# SAM9X75D1G device description
Architecture: ARM926EJ-S; Family: SAM9; Series: SAM9X7
Registers are 32-bit, read-write, reset 0x0 unless marked. A register's access mark holds for its fields unless they carry their own. Offsets are from the block's base; [hi:lo] are bit positions; lines under a group give offsets from that group; {n}, {i} and the like mark numbered series; 'fields as' and 'values as' point back to an identical list.

## LCDC (part 2 of 2) — LCD Controller
Instances: XLCDC 0xF8038000
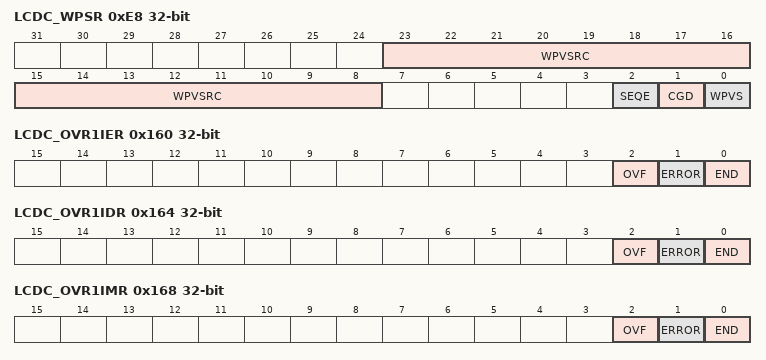
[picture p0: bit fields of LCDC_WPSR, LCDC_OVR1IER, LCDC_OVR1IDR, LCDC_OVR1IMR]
0xE8 LCDC_WPSR ro — Write Protection Status Register
  [23:8] WPVSRC — Write Protection Violation Source
  [2] SEQE — Internal Sequencer Error (cleared on read)
    0=No peripheral internal sequencer error has occurred since the last read of LCDC_WPSR; 1=A peripheral internal sequencer error has occurred since the last read of LCDC_WPSR. This flag can only be set under abnormal operating conditions.
  [1] CGD — Clock Glitch Detected (cleared on read)
    0=The clock monitoring circuitry has not been corrupted since the last read of LCDC_WPSR. Under normal operating conditions, this bit is always cleared.; 1=The clock monitoring circuitry has been corrupted since the last read of LCDC_WPSR. This flag can only be set in case of an abnormal clock signal waveform (glitch).
  [0] WPVS — Write Protection Violation Status
0x160 LCDC_OVR1IER wo reset not defined (atomic set of LCDC_OVR1IMR) — Overlay 1 Interrupt Enable Register
  [2] OVF — Overflow Interrupt Enable
  [1] ERROR — Transfer Error Detected Interrupt Enable
  [0] END — End of Frame DMA Transfer Interrupt Enable
0x164 LCDC_OVR1IDR wo reset not defined (atomic clear of LCDC_OVR1IMR) — Overlay 1 Interrupt Disable Register
  [2] OVF — Overflow Interrupt Disable
  [1] ERROR — Error Interrupt Disable
  [0] END — End of Frame DMA Transfer Interrupt Disable
0x168 LCDC_OVR1IMR ro — Overlay 1 Interrupt Mask Register
  [2] OVF — Overflow Interrupt Mask
  [1] ERROR — Bus Error Detected Interrupt Mask
  [0] END — End of Frame DMA Transfer Interrupt Mask
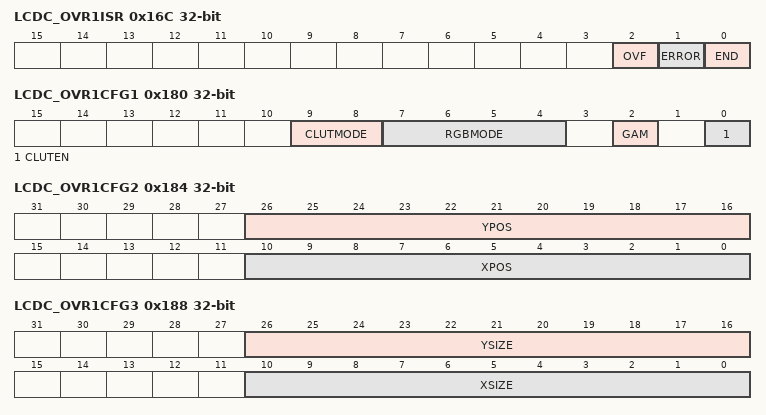
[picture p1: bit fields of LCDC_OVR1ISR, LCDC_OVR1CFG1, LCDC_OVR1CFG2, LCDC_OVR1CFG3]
0x16C LCDC_OVR1ISR ro — Overlay 1 Interrupt Status Register
  [2] OVF — Overflow Detected
    0=No overflow occurred since last read of LCDC_OVR1ISR; 1=An overflow occurred, at least one DMA transfer is still running at the End Of Frame. This flag is reset after a read operation
  [1] ERROR — Bus Error Detected
    0=No system bus error has been detected since the last read of LCDC_OVR1ISR; 1=A system bus error has been detected. This flag is reset after a read operation
  [0] END — End of Frame DMA Transfer
    0=No end of transfer has been detected since last read of LCDC_OVR1ISR; 1=End of transfer has been detected. This flag is reset after a read operation.
0x170 LCDC_OVR1EN — Overlay 1 Enable Register
  [0] ENABLE — Layer Enable
    0=The layer is disabled; 1=The layer is enabled
0x174 LCDC_OVR1CLA — Overlay 1 Color Table Address Register
  [31:2] CLA — Overlay 1 CLUT Address
0x178 LCDC_OVR1FBA — Overlay 1 Frame Buffer Address Register
  [31:0] FBA — Frame Buffer Address
0x17C LCDC_OVR1CFG0 — Overlay 1 Configuration Register 0
  [6:4] BLEN — System Bus Burst Length
    0=INCR1 (System bus access is started as soon as there is enough space in the FIFO to store one data.); 1=INCR4 (System bus access is started as soon as there is enough space in the FIFO to store a total amount of 4 data. A system bus INCR4 Burst is used by default. INCR1 is used for bursts less than 4.); 2=INCR8 (System bus access is started as soon as there is enough space in the FIFO to store a total amount of 8 data. A system bus INCR8 Burst is used by default. INCR4 bursts are used for burst of 4 beats. INCR1 is used for bursts less than 4.); 3=INCR16 (System bus access is started as soon as there is enough space in the FIFO to store a total amount of 16 data. A system bus INCR16 Burst is used by default. INCR8 and INCR4 bursts are respectively used for burst of 8 and 4 beats. INCR1 is used for bursts less than 4.); 4=INCR32 (System bus access is started as soon as there is enough space in the FIFO to store a total amount of 32 data. A system bus INCR32 Burst is used by default. INCR16, INCR8 and INCR4 bursts are respectively used for burst of 16, 8 and 4 beats. INCR1 is used for bursts less than 4.)
0x180 LCDC_OVR1CFG1 — Overlay 1 Configuration Register 1
  [9:8] CLUTMODE — CLUT Mode Input Selection
    0=CLUT_1BPP (CLUT mode set to 1 bit per pixel); 1=CLUT_2BPP (CLUT mode set to 2 bits per pixel); 2=CLUT_4BPP (CLUT mode set to 4 bits per pixel); 3=CLUT_8BPP (CLUT mode set to 8 bits per pixel)
  [7:4] RGBMODE — RGB Mode Input Selection
    0=12BPP_RGB_444; 1=16BPP_ARGB_4444; 2=16BPP_RGBA_4444; 3=16BPP_RGB_565; 4=16BPP_ARGB_1555; 5=18BPP_RGB_666; 6=18BPP_RGB_666PACKED; 7=19BPP_ARGB_1666; 8=19BPP_ARGB_PACKED (19 bpp ARGB 1666 PACKED); 9=24BPP_RGB_888; 10=24BPP_RGB_888_PACKED; 11=25BPP_ARGB_1888; 12=32BPP_ARGB_8888; 13=32BPP_RGBA_8888
  [2] GAM — Gamma Correction
    0=Gamma correction is disabled; 1=Gamma correction is enabled
  [0] CLUTEN — CLUT Mode Enable
    0=RGB mode is selected; 1=CLUT mode is selected
0x184 LCDC_OVR1CFG2 — Overlay 1 Configuration Register 2
  [26:16] YPOS — Vertical Window Position
  [10:0] XPOS — Horizontal Window Position
0x188 LCDC_OVR1CFG3 — Overlay 1 Configuration Register 3
  [26:16] YSIZE — Vertical Window Size
  [10:0] XSIZE — Horizontal Window Size
0x18C LCDC_OVR1CFG4 — Overlay 1 Configuration Register 4
  [31:0] XSTRIDE — Horizontal Stride
0x190 LCDC_OVR1CFG5 — Overlay 1 Configuration Register 5
  [31:0] PSTRIDE — Pixel Stride
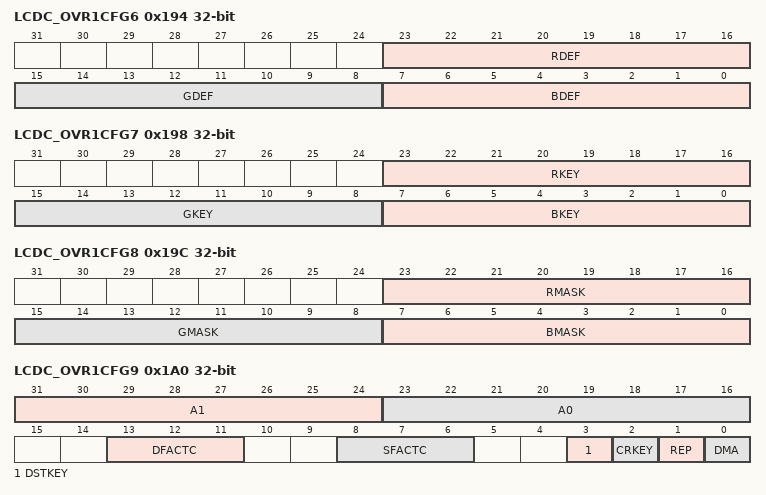
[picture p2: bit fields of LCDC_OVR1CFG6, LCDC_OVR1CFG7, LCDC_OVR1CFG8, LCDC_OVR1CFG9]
0x194 LCDC_OVR1CFG6 — Overlay 1 Configuration Register 6
  [23:16] RDEF — Red Default
  [15:8] GDEF — Green Default
  [7:0] BDEF — Blue Default
0x198 LCDC_OVR1CFG7 — Overlay 1 Configuration Register 7
  [23:16] RKEY — Red Color Component Chroma Key
  [15:8] GKEY — Green Color Component Chroma Key
  [7:0] BKEY — Blue Color Component Chroma Key
0x19C LCDC_OVR1CFG8 — Overlay 1 Configuration Register 8
  [23:16] RMASK — Red Color Component Chroma Key Mask
  [15:8] GMASK — Green Color Component Chroma Key Mask
  [7:0] BMASK — Blue Color Component Chroma Key Mask
0x1A0 LCDC_OVR1CFG9 — Overlay 1 Configuration Register 9
  [31:24] A1 — Alpha 1 Value
  [23:16] A0 — Alpha 0 Value
  [13:11] DFACTC — Destination Factor for the Blending Equation of the Color Component
    0=ZERO (Sets the factor to 0.0.); 1=ONE (Sets the factor to 1.0.); 2=A0 (Sets the factor to A0/255.); 3=A1 (Sets the factor to A1/255.); 4=A0_MULT_AD (Sets the factor to A0 multiplied by Destination Alpha.); 5=M_A0_MULT_AD (Sets the factor to A0 multiplied by Destination Alpha, then sets the factor to one minus the result.); 6=M_A0_MUL_AS (Computes A0 multiplied by source alpha0, then sets the factor to one minus the result.); 7=M_A0 (Computes one minus A0, then sets the factor to one minus the result.)
  [8:6] SFACTC — Source Factor for the Blending Equation of the Color Component
    0=ONE (Sets the factor to 1.0.); 1=ZERO (Sets the factor to 0.0.); 2=A0 (Sets the factor to A0/255.); 3=A0_MULT_AD (Sets the factor to A0 multiplied by Destination Alpha.); 4=A0_MUL_AS (Sets the factor to A0 multiplied by Source Alpha.); 5=M_A0_MUL_AD (Computes A0 multiplied by Destination Alpha, then sets the factor to minus the result .)
  [3] DSTKEY — Destination Color Keying
    0=When CRKEY is enabled, color key is applied on OVR1 pixels, before the blending operation; 1=When CRKEY is enabled, color key is applied on OVR1 pixels, after the blending operation
  [2] CRKEY — Chroma Keying Enable
  [1] REP — Replication Logic
    0=When the selected pixel depth is less than 24 bpp, the pixel is shifted and LSBs are set to 0; 1=When the selected pixel depth is less than 24 bpp, the pixel is shifted and the LSB replicates the MSB
  [0] DMA — DMA Enable
    0=The pixel for the current layer is retrieved from the default color register; 1=The pixel stream is retrieved from the memory
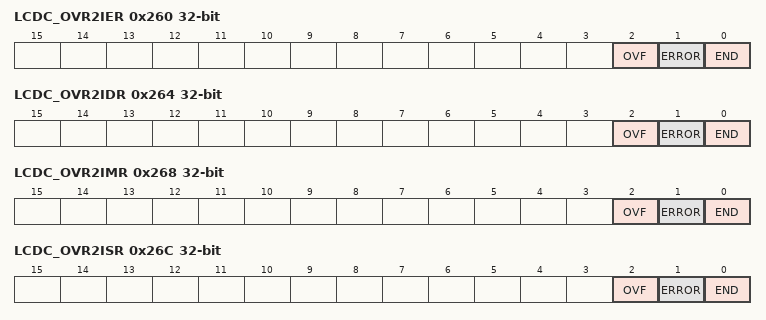
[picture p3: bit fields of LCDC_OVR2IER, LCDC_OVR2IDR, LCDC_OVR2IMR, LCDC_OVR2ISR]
0x260 LCDC_OVR2IER wo reset not defined (atomic set of LCDC_OVR2IMR) — Overlay 2 Interrupt Enable Register
  [2] OVF — Overflow Interrupt Enable
  [1] ERROR — Bus Transfer Error Detected Interrupt Enable
  [0] END — End of Frame DMA Transfer Interrupt Enable
0x264 LCDC_OVR2IDR wo reset not defined (atomic clear of LCDC_OVR2IMR) — Overlay 2 Interrupt Disable Register
  [2] OVF — Overflow Interrupt Disable
  [1] ERROR — Bus Transfer Error Detected Interrupt Disable
  [0] END — End of Frame DMA Transfer Interrupt Disable
0x268 LCDC_OVR2IMR ro — Overlay 2 Interrupt Mask Register
  [2] OVF — Overflow Interrupt Mask
  [1] ERROR — Bus Transfer Error Detected Interrupt Mask
  [0] END — End of Frame DMA Transfer Interrupt Mask
0x26C LCDC_OVR2ISR ro — Overlay 2 Interrupt Status Register
  [2] OVF — Overflow Detected
    0=No overflow occurred since last read of LCDC_OVR2ISR; 1=An overflow occurred, at least one DMA transfer is still running at the End Of Frame. This flag is reset after a read operation
  [1] ERROR — Bus Error Detected
    0=No system bus error has been detected since the last read of LCDC_OVR2ISR; 1=A system bus error has been detected. This flag is reset after a read operation
  [0] END — End of Frame DMA Transfer
    0=No end of transfer has been detected since last read of LCDC_OVR2ISR; 1=End of transfer has been detected. This flag is reset after a read operation.
0x270 LCDC_OVR2EN — Overlay 2 Enable Register
  fields as LCDC_OVR1EN
0x274 LCDC_OVR2CLA — Overlay 2 Color Table Address Register
  [31:2] CLA — Overlay 2 CLUT Address
0x278 LCDC_OVR2FBA — Overlay 2 Frame Buffer Address Register
  [31:0] FBA — Frame Buffer Address
0x27C LCDC_OVR2CFG0 — Overlay 2 Configuration Register 0
  [6:4] BLEN — System Bus Burst Length
    0=INCR1 (System bus access is started as soon as there is enough space in the FIFO to store one data.); 1=INCR4 (System bus access is started as soon as there is enough space in the FIFO to store a total amount of 4 data. A system bus INCR4 Burst is used by default. INCR1 is used for bursts less than 4.); 2=INCR8 (System bus access is started as soon as there is enough space in the FIFO to store a total amount of 8 data. A system bus INCR8 Burst is used by default. INCR4 bursts are used for bursts of 4 beats. INCR1 is used for bursts less than 4.); 3=INCR16 (System bus access is started as soon as there is enough space in the FIFO to store a total amount of 16 data. A system bus INCR16 Burst is used by default. INCR8 and INCR4 bursts are respectively used for bursts of 8 and 4 beats. INCR1 is used for bursts less than 4.); 4=INCR32 (System bus access is started as soon as there is enough space in the FIFO to store a total amount of 32 data. A system bus INCR32 Burst is used by default. INCR16, INCR8 and INCR4 bursts are respectively used for bursts of 16, 8 and 4 beats. INCR1 is used for bursts less than 4.)
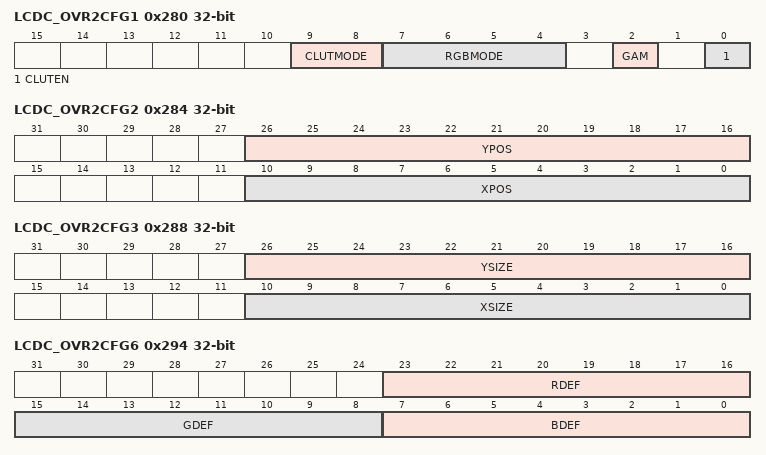
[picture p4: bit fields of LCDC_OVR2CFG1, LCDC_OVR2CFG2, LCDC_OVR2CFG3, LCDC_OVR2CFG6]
0x280 LCDC_OVR2CFG1 — Overlay 2 Configuration Register 1
  fields as LCDC_OVR1CFG1
0x284 LCDC_OVR2CFG2 — Overlay 2 Configuration Register 2
  fields as LCDC_OVR1CFG2
0x288 LCDC_OVR2CFG3 — Overlay 2 Configuration Register 3
  fields as LCDC_OVR1CFG3
0x28C LCDC_OVR2CFG4 — Overlay 2 Configuration Register 4
  [31:0] XSTRIDE — Horizontal Stride
0x290 LCDC_OVR2CFG5 — Overlay 2 Configuration Register 5
  [31:0] PSTRIDE — Pixel Stride
0x294 LCDC_OVR2CFG6 — Overlay 2 Configuration Register 6
  fields as LCDC_OVR1CFG6
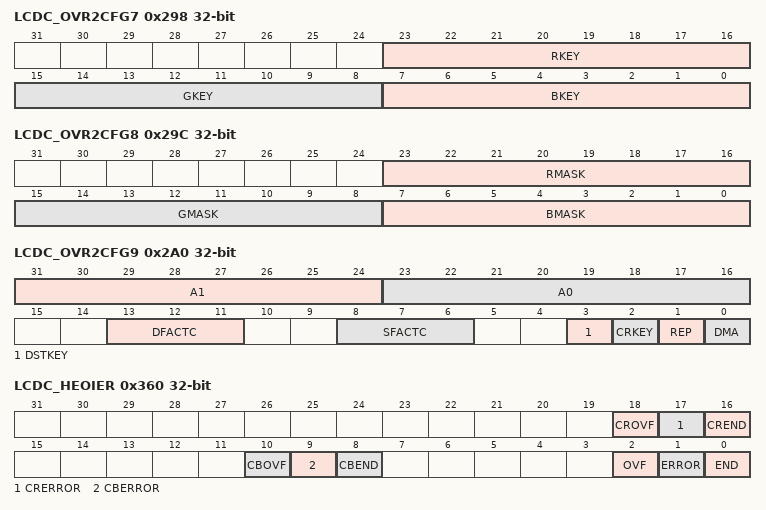
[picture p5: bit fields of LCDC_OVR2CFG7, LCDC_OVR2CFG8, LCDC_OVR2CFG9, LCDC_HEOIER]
0x298 LCDC_OVR2CFG7 — Overlay 2 Configuration Register 7
  fields as LCDC_OVR1CFG7
0x29C LCDC_OVR2CFG8 — Overlay 2 Configuration Register 8
  fields as LCDC_OVR1CFG8
0x2A0 LCDC_OVR2CFG9 — Overlay 2 Configuration Register 9
  [31:24] A1 — Alpha 1 Value
  [23:16] A0 — Alpha 0 Value
  [13:11] DFACTC — Destination Factor for the Blending Equation of the Color Component
    0=ZERO (Sets the factor to 0.0.); 1=ONE (Sets the factor to 1.0.); 2=A0 (Sets the factor to A0/255.); 3=A1 (Sets the factor to A1/255.); 4=A0_MULT_AD (Sets the factor to A0 multiplied by Destination Alpha.); 5=M_A0_MULT_AD (Sets the factor to A0 multiplied by Destination Alpha, then set the factor one minus the result.); 6=M_A0_MUL_AS (Computes A0 multiplied by source alpha0, then sets the factor to one minus the result.); 7=M_A0 (Computes one minus A0, then sets the factor to one minus the result.)
  [8:6] SFACTC — Source Factor for the Blending Equation of the Color Component
    0=ONE (Sets the factor to 1.0.); 1=ZERO (Sets the factor to 0.0.); 2=A0 (Sets the factor to A0/255.); 3=A0_MULT_AD (Sets the factor to A0 multiplied by Destination Alpha.); 4=A0_MUL_AS (Sets the factor to A0 multiplied by Source Alpha.); 5=M_A0_MUL_AD (Computes A0 multiplied by Destination Alpha, then sets the factor to minus the result.)
  [3] DSTKEY — Destination Color Keying
    0=When CRKEY is enabled, color key is applied on OVR2 pixels, before the blending operation; 1=When CRKEY is enabled, color key is applied on OVR2 pixels, after the blending operation
  [2] CRKEY — Chroma Keying
  [1] REP — Replication Logic
    values as LCDC_OVR1CFG9.REP
  [0] DMA — DMA Enable
    values as LCDC_OVR1CFG9.DMA
0x360 LCDC_HEOIER wo reset not defined (atomic set of LCDC_HEOIMR) — High-End Overlay Interrupt Enable Register
  [18] CROVF — Overflow for Cr Chroma Plane Interrupt Enable
  [17] CRERROR — Bus Transfer Error Detected for Cr Chroma Plane Interrupt Enable
  [16] CREND — End of Frame DMA for Cr Chroma Plane Transfer Interrupt Enable
  [10] CBOVF — Overflow for Cb or CbCr Chroma Plane Interrupt Enable
  [9] CBERROR — Bus Transfer Error Detected for Cb or CbCr Chroma Plane Interrupt Enable
  [8] CBEND — End of Frame DMA Transfer for Cb or CbCr Chroma Plane Interrupt Enable
  [2] OVF — Overflow Interrupt Enable
  [1] ERROR — Bus Transfer Error Detected Interrupt Enable
  [0] END — End of Frame DMA Transfer Interrupt Enable
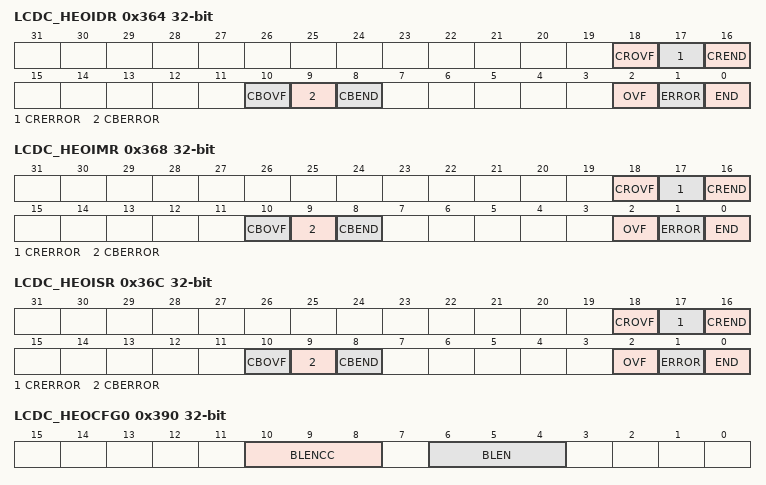
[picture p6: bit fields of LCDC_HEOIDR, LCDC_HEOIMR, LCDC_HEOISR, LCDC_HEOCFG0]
0x364 LCDC_HEOIDR wo reset not defined (atomic clear of LCDC_HEOIMR) — High-End Overlay Interrupt Disable Register
  [18] CROVF — Overflow for Cr Chroma Plane Interrupt Disable
  [17] CRERROR — Bus Transfer Error Detected for Cr Chroma Plane Interrupt Disable
  [16] CREND — End of Frame DMA Transfer for Cr Chroma Plane Interrupt Disable
  [10] CBOVF — Overflow for Cb or CbCr Chroma Plane Interrupt Disable
  [9] CBERROR — Bus Transfer Error Detected for Cb or CbCr Chroma Plane Interrupt Disable
  [8] CBEND — End of Frame DMA Transfer for Cb or CbCr Chroma Plane Interrupt Disable
  [2] OVF — Overflow Interrupt Disable
  [1] ERROR — Bus Transfer Error Detected Interrupt Disable
  [0] END — End of Frame DMA Transfer Interrupt Disable
0x368 LCDC_HEOIMR ro — High-End Overlay Interrupt Mask Register
  [18] CROVF — Overflow for Cr Chroma Plane Interrupt Mask
  [17] CRERROR — Bus Transfer Error Detected for Cr Chroma Plane Interrupt Mask
  [16] CREND — End of Frame DMA Transfer for Cr Chroma Plane Interrupt Mask
  [10] CBOVF — Overflow for Cb or CbCr Chroma Plane Interrupt Mask
  [9] CBERROR — Bus Transfer Error Detected for Cb or CbCr Chroma Plane Interrupt Mask
  [8] CBEND — End of Frame DMA Transfer for Cb or CbCr Chroma Plane Interrupt Mask
  [2] OVF — Overflow Interrupt Mask
  [1] ERROR — Bus Transfer Error Detected Interrupt Mask
  [0] END — End of Frame DMA Transfer Interrupt Mask
0x36C LCDC_HEOISR ro — High-End Overlay Interrupt Status Register
  [18] CROVF — Overflow Detected for Cr plane
    0=No overflow occurred since last read of LCDC_HEOISR; 1=An overflow occurred, at least one DMA transfer is still running at the End Of Frame. This flag is reset after a read operation.
  [17] CRERROR — Bus Transfer Error detected for Cr plane
    0=No system bus error has been detected since the last read of LCDC_HEOISR; 1=A system bus error has been detected. This flag is reset after a read operation.
  [16] CREND — End of Frame DMA Transfer for Cr plane
    0=No end of transfer has been detected since last read of LCDC_HEOISR; 1=End of transfer has been detected. This flag is reset after a read operation.
  [10] CBOVF — Overflow Detected for Cb or CbCr plane
    values as CROVF
  [9] CBERROR — Bus Transfer Error Detected for Cb or CbCr plane
    values as CRERROR
  [8] CBEND — End of Frame DMA Transfer for Cb or CbCr plane
    values as CREND
  [2] OVF — Overflow Detected
    0=No overflow occurred since last read of LCDC_HEOISR; 1=An overflow occurred, at least one DMA transfer is still running at the End Of Frame. This flag is reset after a read operation
  [1] ERROR — Bus Error Detected
    values as CRERROR
  [0] END — End of Frame DMA Transfer
    values as CREND
0x370 LCDC_HEOEN — High-End Overlay Enable Register
  [0] ENABLE — Overlay Enable
    0=The layer is disabled; 1=The layer is enabled
0x374 LCDC_HEOCLA — High-End Overlay Table Address Register
  [31:2] CLA — High-End Overlay CLUT Address
{0x378+0xC*i} LCDC_HEO[{i}] (i=0..1) group
  0x00 LCDC_HEOYFBA — High-End Overlay Y Frame Buffer x Addr
    [31:0] FBA — Frame Buffer Address
  0x04 LCDC_HEOCBFBA — High-End Overlay Cb Frame Buffer x Addr
    [31:0] CBFBA — Cb or CbCr Plane Frame Buffer Address
  0x08 LCDC_HEOCRFBA — High-End Overlay Cr Frame Buffer x Addr
    [31:0] CRFBA — Cr Chroma Plane Frame Buffer Address
0x390 LCDC_HEOCFG0 — High-End Overlay Configuration Register 0
  [10:8] BLENCC — System Bus Burst Length for Cb-Cr Channel
    values as LCDC_OVR2CFG0.BLEN
  [6:4] BLEN — System Bus Burst Length
    values as LCDC_OVR2CFG0.BLEN
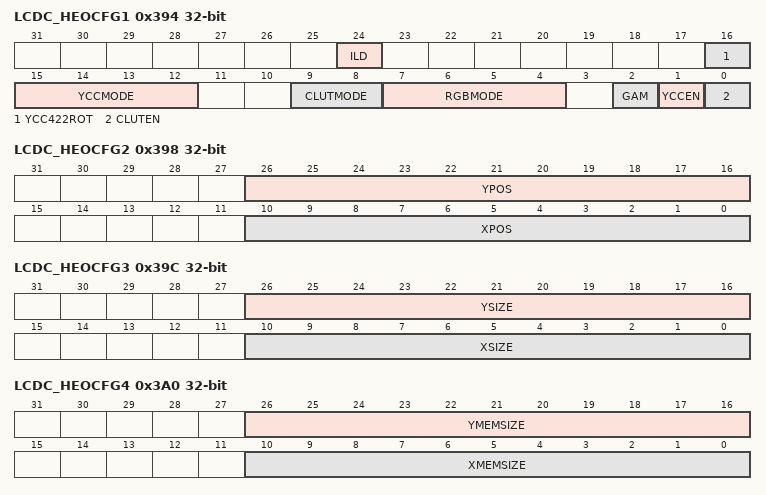
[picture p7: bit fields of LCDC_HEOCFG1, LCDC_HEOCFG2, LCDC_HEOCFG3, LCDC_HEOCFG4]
0x394 LCDC_HEOCFG1 — High-End Overlay Configuration Register 1
  [24] ILD
  [16] YCC422ROT
  [15:12] YCCMODE
  [9:8] CLUTMODE — CLUT Mode Input Selection
    values as LCDC_OVR1CFG1.CLUTMODE
  [7:4] RGBMODE — RGB Mode Input Selection
    values as LCDC_OVR1CFG1.RGBMODE
  [2] GAM — Gamma Correction
    values as LCDC_OVR1CFG1.GAM
  [1] YCCEN — YCbCr Color Space Enable
    0=Color space is RGB; 1=Color space is YCbCr
  [0] CLUTEN — CLUT Mode Enable
    0=RGB mode is selected; 1=CLUT mode is selected
0x398 LCDC_HEOCFG2 — High-End Overlay Configuration Register 2
  fields as LCDC_OVR1CFG2
0x39C LCDC_HEOCFG3 — High-End Overlay Configuration Register 3
  fields as LCDC_OVR1CFG3
0x3A0 LCDC_HEOCFG4 — High-End Overlay Configuration Register 4
  [26:16] YMEMSIZE — Vertical image Size in Memory
  [10:0] XMEMSIZE — Horizontal image Size in Memory
0x3A4 LCDC_HEOCFG5 — High-End Overlay Configuration Register 5
  [31:0] XSTRIDE — Horizontal Stride
0x3A8 LCDC_HEOCFG6 — High-End Overlay Configuration Register 6
  [31:0] PSTRIDE — Pixel Stride
0x3AC LCDC_HEOCFG7 — High-End Overlay Configuration Register 7
  [31:0] CCXSTRIDE — CbCr Horizontal Stride
0x3B0 LCDC_HEOCFG8 — High-End Overlay Configuration Register 8
  [31:0] CCPSTRIDE — CbCr Pixel Stride
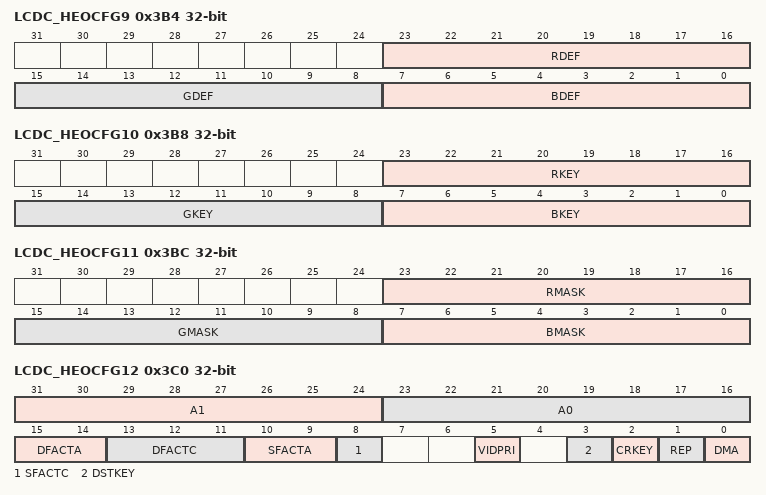
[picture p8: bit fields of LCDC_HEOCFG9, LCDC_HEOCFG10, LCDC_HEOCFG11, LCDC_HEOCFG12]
0x3B4 LCDC_HEOCFG9 — High-End Overlay Configuration Register 9
  fields as LCDC_OVR1CFG6
0x3B8 LCDC_HEOCFG10 — High-End Overlay Configuration Register 10
  fields as LCDC_OVR1CFG7
0x3BC LCDC_HEOCFG11 — High-End Overlay Configuration Register 11
  fields as LCDC_OVR1CFG8
0x3C0 LCDC_HEOCFG12 — High-End Overlay Configuration Register 12
  [31:24] A1 — Alpha 1 Value
  [23:16] A0 — Alpha 0 Value
  [15:14] DFACTA
  [13:11] DFACTC — Destination Factor for the Blending Equation of the Color Component
    0=ZERO (Sets the factor to 0.0.); 1=ONE (Sets the factor to 1.0.); 2=A0 (Sets the factor to A0/255.); 3=A1 (Sets the factor to A1/255.); 4=A0_MULT_AD (Sets the factor to A0 multiplied by Destination Alpha.); 5=M_A0_MULT_AD (Sets the factor to A0 multiplied by Destination Alpha, then sets the factor one minus the result.); 6=M_A0_MUL_AS (Computes A0 multiplied by source alpha0, then set the factor to one minus the result.); 7=M_A0 (Computes one minus A0, then set the factor to one minus the result.)
  [10:9] SFACTA
  [8] SFACTC — Source Factor for the Blending Equation of the Color Component
    values as LCDC_OVR2CFG9.SFACTC
  [5] VIDPRI — Video Priority Mode
    0=HEO is located below OVR1; 1=HEO is located above OVR1
  [3] DSTKEY — Destination Color Keying
    0=When CRKEY is enabled, color key is applied on HEO pixels, before blending operation; 1=When CRKEY is enabled, color key is applied on HEO pixels, after blending operation
  [2] CRKEY — Chroma Keying
  [1] REP — Replication Logic
    values as LCDC_OVR1CFG9.REP
  [0] DMA — DMA Enable
    values as LCDC_OVR1CFG9.DMA
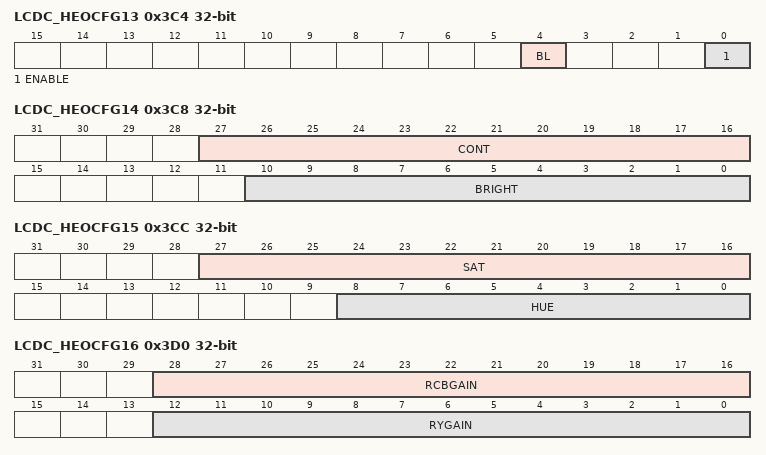
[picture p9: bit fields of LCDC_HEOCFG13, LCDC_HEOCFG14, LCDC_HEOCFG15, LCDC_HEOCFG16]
0x3C4 LCDC_HEOCFG13 — High-End Overlay Configuration Register 13
  [4] BL — Black Level
    0=Black level offset is disabled; 1=Black level offset is enabled
  [0] ENABLE — Contrast, Brightness Hue and Saturation Enable
    0=CBHS is disabled; 1=CBHS is enabled
0x3C8 LCDC_HEOCFG14 — High-End Overlay Configuration Register 14
  [27:16] CONT — Contrast Value
  [10:0] BRIGHT — Brightness Value
0x3CC LCDC_HEOCFG15 — High-End Overlay Configuration Register 15
  [27:16] SAT — Saturation Value
  [8:0] HUE — Hue Value in Degrees
0x3D0 LCDC_HEOCFG16 — High-End Overlay Configuration Register 16
  [28:16] RCBGAIN — Color Space Conversion CB Coefficient for Red Component 1:2:10 Format
  [12:0] RYGAIN — Color Space Conversion Y Coefficient for Red Component 1:2:10 Format
0x3D4 LCDC_HEOCFG17 — High-End Overlay Configuration Register 17
  [12:0] RCRGAIN — Color Space Conversion CR Coefficient for Red Component 1:2:10 Format
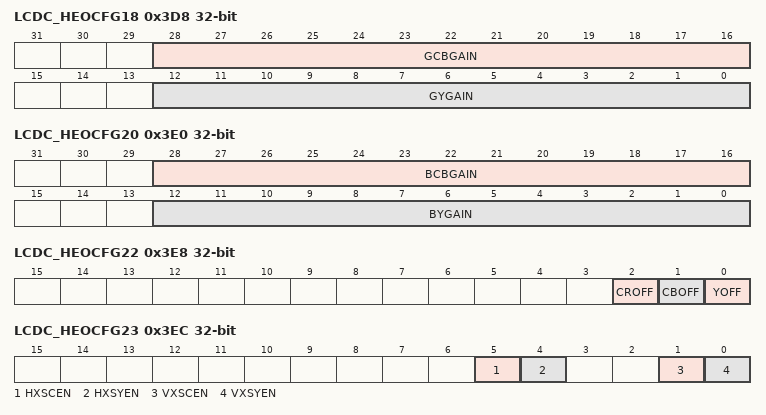
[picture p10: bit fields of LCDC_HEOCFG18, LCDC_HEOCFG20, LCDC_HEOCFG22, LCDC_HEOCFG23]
0x3D8 LCDC_HEOCFG18 — High-End Overlay Configuration Register 18
  [28:16] GCBGAIN — Color Space Conversion CB Coefficient for Green Component 1:2:10 Format
  [12:0] GYGAIN — Color Space Conversion Y Coefficient for Green Component 1:2:10 Format
0x3DC LCDC_HEOCFG19 — High-End Overlay Configuration Register 19
  [12:0] GCRGAIN — Color Space Conversion CR Coefficient for Green Component 1:2:10 Format
0x3E0 LCDC_HEOCFG20 — High-End Overlay Configuration Register 20
  [28:16] BCBGAIN — Color Space Conversion CB Coefficient for Blue Component 1:2:10 Format
  [12:0] BYGAIN — Color Space Conversion Y Coefficient for Blue Component 1:2:10 Format
0x3E4 LCDC_HEOCFG21 — High-End Overlay Configuration Register 21
  [12:0] BCRGAIN — Color Space Conversion Y Coefficient for Blue Component 1:2:10 Format
0x3E8 LCDC_HEOCFG22 — High-End Overlay Configuration Register 22
  [2] CROFF — Red Chroma Offset
  [1] CBOFF — Blue Chroma Offset
  [0] YOFF — Luma Offset
0x3EC LCDC_HEOCFG23 — High-End Overlay Configuration Register 23
  [5] HXSCEN — Horizontal Scaler Chroma Component Enable
  [4] HXSYEN — Horizontal Scaler Luma Component Enable
  [1] VXSCEN — Vertical Scaler Chroma Component Enable
  [0] VXSYEN — Vertical Scaler Luma Component Enable
0x3F0 LCDC_HEOCFG24 — High-End Overlay Configuration Register 24
  [23:0] VXSYFACT — Vertical Luma Scaling Factor
0x3F4 LCDC_HEOCFG25 — High-End Overlay Configuration Register 25
  [23:0] VXSCFACT — Vertical Chroma Scaling Factor
0x3F8 LCDC_HEOCFG26 — High-End Overlay Configuration Register 26
  [23:0] HXSYFACT — Horizontal Luma Scaling factor
0x3FC LCDC_HEOCFG27 — High-End Overlay Configuration Register 27
  [23:0] HXSCFACT — Horizontal Chroma Scaling Factor
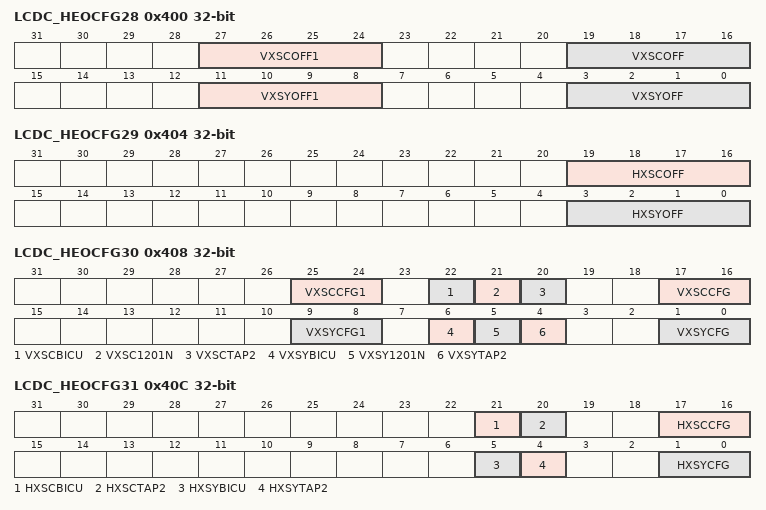
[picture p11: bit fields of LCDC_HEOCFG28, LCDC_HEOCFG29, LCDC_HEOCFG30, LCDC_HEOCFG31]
0x400 LCDC_HEOCFG28 — High-End Overlay Configuration Register 28
  [27:24] VXSCOFF1 — Vertical Scaler Chroma Default Phase for Field 1
  [19:16] VXSCOFF — Vertical Scaler Chroma Default Phase for Field 0 or Progressive Scan
  [11:8] VXSYOFF1 — Vertical Scaler Luma Default Phase for Field 1
  [3:0] VXSYOFF — Vertical Scaler Luma Default Phase for Field 0 or Progressive Scan
0x404 LCDC_HEOCFG29 — High-End Overlay Configuration Register 29
  [19:16] HXSCOFF — Hozontal Scaler Chroma Offset
  [3:0] HXSYOFF — Horizontal Scaler Luma Offset
0x408 LCDC_HEOCFG30 — High-End Overlay Configuration Register 30
  [25:24] VXSCCFG1 — Vertical Scaler Chroma Configuration for Field 1(only used for YCrCb Interlaced Frame Content)
  [22] VXSCBICU — Vertical Scaler Predefined Bicubic Taps Selected for Chroma/GB Component
    0=Bicubic taps values are not selected; 1=Bicubic taps values are selected
  [21] VXSC1201N — Vertical Scaler Bilinear 2 Taps Position among 4 Taps Filter for Chroma/GB Component
    0=When selected, bilinear taps values are located on 0 and 1 positions (left aligned); 1=When selected, bilinear taps values are located on 0 and 1 positions (center aligned)
  [20] VXSCTAP2 — Vertical Scaler Predefined Bilinear 2 Taps Selected for Chroma/GB Component
    0=Bilinear 2 taps value not selected; 1=Bilinear 2 taps value selected
  [17:16] VXSCCFG — Vertical Scaler Chroma/GB Configuration for Field 0 or Progressive Scan
  [9:8] VXSYCFG1 — Vertical Scaler Chroma/GB Configuration for Field 1 (only used for interlaced frame content)
  [6] VXSYBICU — Vertical Scaler Predefined Bicubic Taps Selected for Luma/AR Component
    values as VXSCBICU
  [5] VXSY1201N — Vertical Scaler Bilinear 2 Taps Position among 4 Filter Taps for Luma/AR Component
    0=When selected, bilinear tap values are located on 0 and 1 positions (left-aligned); 1=When selected, bilinear tap values are located on 0 and 1 positions (center-aligned)
  [4] VXSYTAP2 — Vertical Scaler Predefined Bilinear 2 Taps Selected for Luma/AR Component
    values as VXSCTAP2
  [1:0] VXSYCFG — Vertical Scaler Luma/AR Configuration for Field 0 or Progressive Scan
0x40C LCDC_HEOCFG31 — High-End Overlay Configuration Register 31
  [21] HXSCBICU — Horizontal Scaler Bicubic Coefficients Selected for Chroma Component
    values as LCDC_HEOCFG30.VXSCBICU
  [20] HXSCTAP2 — Horizontal Scaler Predefined Bilinear 2 Taps Selected for Chroma Component
    values as LCDC_HEOCFG30.VXSCTAP2
  [17:16] HXSCCFG — Horizontal Scaler Chroma/GB Configuration
  [5] HXSYBICU — Horizontal Scaler Predefined Bicubic Taps Selected for Luma/AR Component
    values as LCDC_HEOCFG30.VXSCBICU
  [4] HXSYTAP2 — Horizontal Scaler Predefined Bilinear 2 Taps Selected for Luma/AR Component
    values as LCDC_HEOCFG30.VXSCTAP2
  [1:0] HXSYCFG — Horizontal Scaler Luma Configuration
{0x410+8i} LCDC_HEOVTAP[{i}] (i=0..15) group
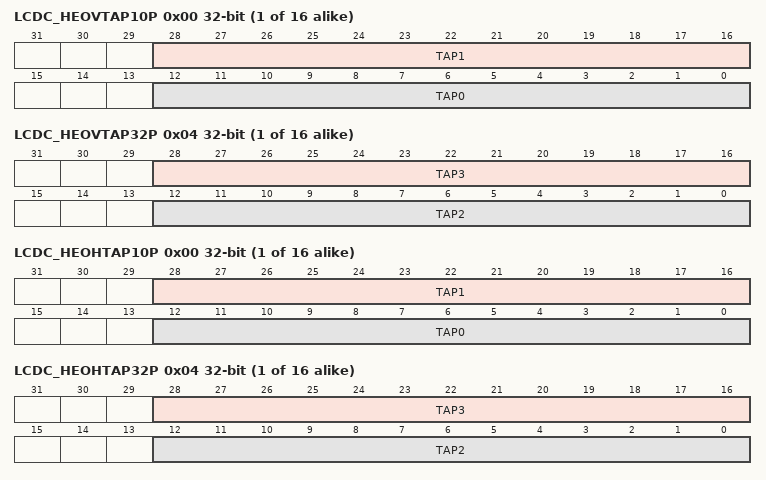
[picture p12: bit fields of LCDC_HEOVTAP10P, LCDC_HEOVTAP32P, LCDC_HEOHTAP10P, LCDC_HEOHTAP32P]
  0x00 LCDC_HEOVTAP10P — High-End Overlay VXS T10 Phi Register
    [28:16] TAP1 — Vertical Filter Tap 1 Coefficient
    [12:0] TAP0 — Vertical Filter Tap 0 Coefficient
  0x04 LCDC_HEOVTAP32P — High-End Overlay VXS T32 Phi Register
    [28:16] TAP3 — Vertical Filter Tap 3 Coefficient
    [12:0] TAP2 — Vertical Filter Tap 2 Coefficient
{0x490+8i} LCDC_HEOHTAP[{i}] (i=0..15) group
  0x00 LCDC_HEOHTAP10P — High-End Overlay HXS T10 Phi Register
    [28:16] TAP1 — Horitzontal Filter Tap 1 Coefficient
    [12:0] TAP0 — Horizontal Filter Tap 0 Coefficient
  0x04 LCDC_HEOHTAP32P — High-End Overlay HXS T32 Phi Register
    [28:16] TAP3 — Horizontal Filter Tap 3 Coefficient
    [12:0] TAP2 — Horizontal Filter Tap 2 Coefficient
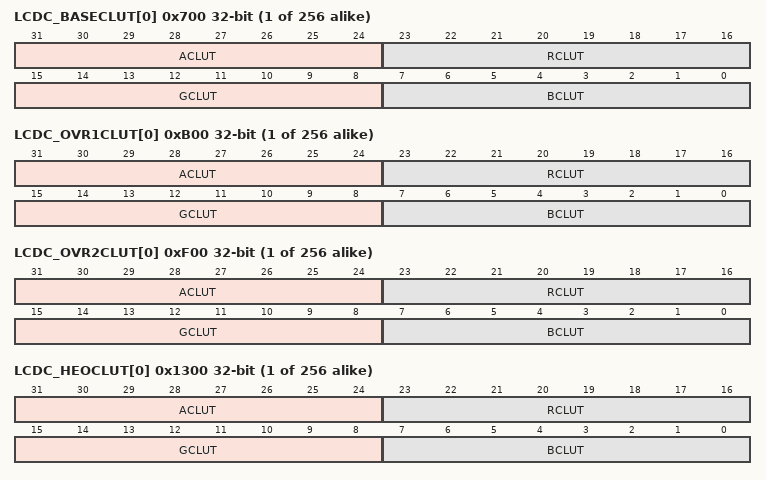
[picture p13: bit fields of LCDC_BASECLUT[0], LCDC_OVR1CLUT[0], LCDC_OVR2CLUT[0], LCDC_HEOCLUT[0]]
{0x700+4i} LCDC_BASECLUT[{i}] (i=0..255) — Base Layer CLUT Register x
  [31:24] ACLUT — Alpha Component Entry
  [23:16] RCLUT — Red Color Entry
  [15:8] GCLUT — Green Color Entry
  [7:0] BCLUT — Blue Color Entry
{0xB00+4i} LCDC_OVR1CLUT[{i}] (i=0..255) — Overlay 1 CLUT Register x
  [31:24] ACLUT — Alpha Color Entry
  [23:16] RCLUT — Red Color Entry
  [15:8] GCLUT — Green Color Entry
  [7:0] BCLUT — Blue Color Entry
{0xF00+4i} LCDC_OVR2CLUT[{i}] (i=0..255) — Overlay 2 CLUT Register x
  fields as LCDC_OVR1CLUT[0]
{0x1300+4i} LCDC_HEOCLUT[{i}] (i=0..255) — High-End Overlay CLUT Register x
  fields as LCDC_OVR1CLUT[0]
